AUTOSAR XML (schema 00046)
package /ComponentTypes
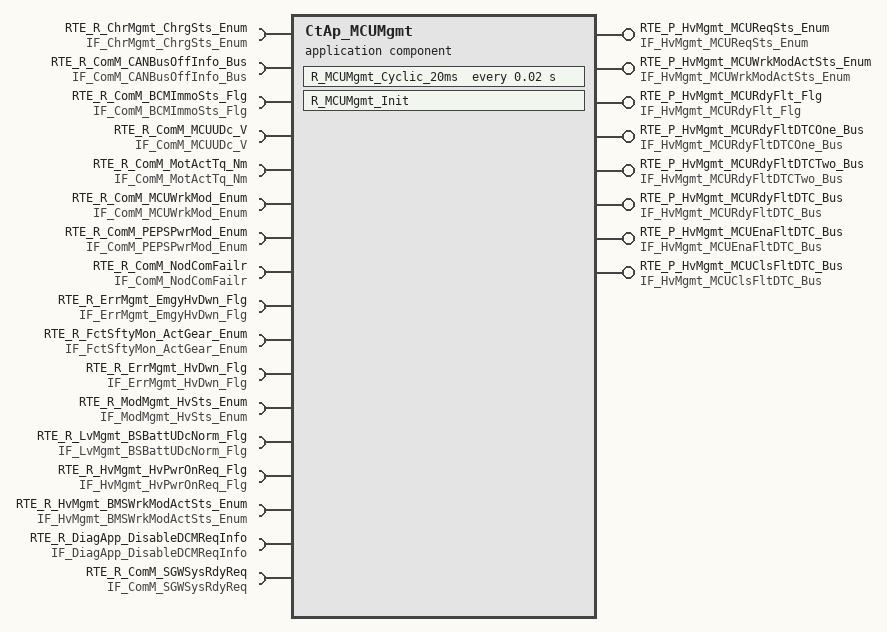
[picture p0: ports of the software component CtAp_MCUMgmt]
  application sw component type CtAp_MCUMgmt
    8 x provide port:
      RTE_P_HvMgmt_MCUReqSts_Enum: nonqueued-sender-com-spec{data-element=tec_HvMgmt_MCUReqSts_Enum, init-value=0}, provided-interface=IF_HvMgmt_MCUReqSts_Enum
      RTE_P_HvMgmt_MCUWrkModActSts_Enum: nonqueued-sender-com-spec{data-element=tec_HvMgmt_MCUWrkModActSts_Enum, init-value=0}, provided-interface=IF_HvMgmt_MCUWrkModActSts_Enum
      RTE_P_HvMgmt_MCURdyFlt_Flg: nonqueued-sender-com-spec{data-element=tec_HvMgmt_MCURdyFlt_Flg, init-value=0}, provided-interface=IF_HvMgmt_MCURdyFlt_Flg
      RTE_P_HvMgmt_MCURdyFltDTCOne_Bus: nonqueued-sender-com-spec{data-element=tec_HvMgmt_MCURdyFltDTCOne_Bus, init-value=fields=[HvMgmt_MonStatMCURdyFltDTCOne:0, HvMgmt_MonResMCURdyFltDTCOne:0, HvMgmt_ErrStatMCURdyFltDTCOne:0, HvMgmt_ErrResMCURdyFltDTCOne:0]}, provided-interface=IF_HvMgmt_MCURdyFltDTCOne_Bus
      RTE_P_HvMgmt_MCURdyFltDTCTwo_Bus: nonqueued-sender-com-spec{data-element=tec_HvMgmt_MCURdyFltDTCTwo_Bus, init-value=fields=[HvMgmt_MonStatMCURdyFltDTCTwo:0, HvMgmt_MonResMCURdyFltDTCTwo:0, HvMgmt_ErrStatMCURdyFltDTCTwo:0, HvMgmt_ErrResMCURdyFltDTCTwo:0]}, provided-interface=IF_HvMgmt_MCURdyFltDTCTwo_Bus
      RTE_P_HvMgmt_MCURdyFltDTC_Bus: nonqueued-sender-com-spec{data-element=tec_HvMgmt_MCURdyFltDTC_Bus, init-value=fields=[HvMgmt_MonStatMCURdyFltDTC:0, HvMgmt_MonResMCURdyFltDTC:0, HvMgmt_ErrStatMCURdyFltDTC:0, HvMgmt_ErrResMCURdyFltDTC:0]}, provided-interface=IF_HvMgmt_MCURdyFltDTC_Bus
      RTE_P_HvMgmt_MCUEnaFltDTC_Bus: nonqueued-sender-com-spec{data-element=tec_HvMgmt_MCUEnaFltDTC_Bus, init-value=fields=[HvMgmt_MonStatMCUEnaFltDTC:0, HvMgmt_MonResMCUEnaFltDTC:0, HvMgmt_ErrStatMCUEnaFltDTC:0, HvMgmt_ErrResMCUEnaFltDTC:0]}, provided-interface=IF_HvMgmt_MCUEnaFltDTC_Bus
      RTE_P_HvMgmt_MCUClsFltDTC_Bus: nonqueued-sender-com-spec{data-element=tec_HvMgmt_MCUClsFltDTC_Bus, init-value=fields=[HvMgmt_MonStatMCUClsFltDTC:0, HvMgmt_MonResMCUClsFltDTC:0, HvMgmt_ErrStatMCUClsFltDTC:0, HvMgmt_ErrResMCUClsFltDTC:0]}, provided-interface=IF_HvMgmt_MCUClsFltDTC_Bus
    17 x require port:
      RTE_R_ChrMgmt_ChrgSts_Enum: nonqueued-receiver-com-spec{data-element=tec_ChrMgmt_ChrgSts_Enum, filter=data-filter-type=ALWAYS, init-value=0}, required-interface=IF_ChrMgmt_ChrgSts_Enum
      RTE_R_ComM_CANBusOffInfo_Bus: required-interface=IF_ComM_CANBusOffInfo_Bus
        required-com-specs:
          data-element=tec_ComM_EPTCANBusOffInfo_Bus, filter=data-filter-type=ALWAYS, init-value=fields=[ComM_MonStatEPTCANBusOffInfo:0, ComM_MonResEPTCANBusOffInfo:0, ComM_ErrStatEPTCANBusOffInfo:0, ComM_ErrResEPTCANBusOffInfo:0]
          data-element=tec_ComM_CHCANBusOffInfo_Bus, filter=data-filter-type=ALWAYS, init-value=fields=[ComM_MonStatCHCANBusOffInfo:0, ComM_MonResCHCANBusOffInfo:0, ComM_ErrStatCHCANBusOffInfo:0, ComM_ErrResCHCANBusOffInfo:0]
          data-element=tec_ComM_EPTCANBusOffDTCInfo_Bus, filter=data-filter-type=ALWAYS, init-value=fields=[ComM_MonStatEPTCANBusOffDTCInfo:0, ComM_MonResEPTCANBusOffDTCInfo:0, ComM_ErrStatEPTCANBusOffDTCInfo:0, ComM_ErrResEPTCANBusOffDTCInfo:0]
          data-element=tec_ComM_CHCANBusOffDTCInfo_Bus, filter=data-filter-type=ALWAYS, init-value=fields=[ComM_MonStatCHCANBusOffDTCInfo:0, ComM_MonResCHCANBusOffDTCInfo:0, ComM_ErrStatCHCANBusOffDTCInfo:0, ComM_ErrResCHCANBusOffDTCInfo:0]
          data-element=tec_ComM_DCCANBusOffDTCInfo_Bus, init-value=fields=[ComM_MonStatDCCANDTCBusOffInfo:0, ComM_MonResDCCANDTCBusOffInfo:0, ComM_ErrStatDCCANDTCBusOffInfo:0, ComM_ErrResDCCANDTCBusOffInfo:0]
          data-element=tec_ComM_DCCANBusOffInfo_Bus, init-value=fields=[ComM_MonStatDCCANBusOffInfo:0, ComM_MonResDCCANBusOffInfo:0, ComM_ErrStatDCCANBusOffInfo:0, ComM_ErrResDCCANBusOffInfo:0]
      RTE_R_ComM_BCMImmoSts_Flg: nonqueued-receiver-com-spec{data-element=tec_ComM_BCMImmoSts_Flg, filter=data-filter-type=ALWAYS, init-value=0}, required-interface=IF_ComM_BCMImmoSts_Flg
      RTE_R_ComM_MCUUDc_V: nonqueued-receiver-com-spec{data-element=tec_ComM_MCUUDc_V, filter=data-filter-type=ALWAYS, init-value=0}, required-interface=IF_ComM_MCUUDc_V
      RTE_R_ComM_MotActTq_Nm: nonqueued-receiver-com-spec{data-element=tec_ComM_MotActTq_Nm, filter=data-filter-type=ALWAYS, init-value=0}, required-interface=IF_ComM_MotActTq_Nm
      RTE_R_ComM_MCUWrkMod_Enum: nonqueued-receiver-com-spec{data-element=tec_ComM_MCUWrkMod_Enum, filter=data-filter-type=ALWAYS, init-value=0}, required-interface=IF_ComM_MCUWrkMod_Enum
      RTE_R_ComM_PEPSPwrMod_Enum: nonqueued-receiver-com-spec{data-element=tec_ComM_PEPSPwrMod_Enum, filter=data-filter-type=ALWAYS, init-value=0}, required-interface=IF_ComM_PEPSPwrMod_Enum
      RTE_R_ComM_NodComFailr: required-interface=IF_ComM_NodComFailr
        required-com-specs:
          data-element=tec_ComM_SGWNodComFailr_Flg, filter=data-filter-type=ALWAYS, init-value=0
          data-element=tec_ComM_CGWNodComFailr_Flg, filter=data-filter-type=ALWAYS, init-value=0
          data-element=tec_ComM_TCUNodComFailr_Flg, filter=data-filter-type=ALWAYS, init-value=0
          data-element=tec_ComM_BCMNodComFailr_Flg, filter=data-filter-type=ALWAYS, init-value=0
          data-element=tec_ComM_PRNDNodComFailr_Flg, filter=data-filter-type=ALWAYS, init-value=0
          data-element=tec_ComM_IVINodComFailr_Flg, filter=data-filter-type=ALWAYS, init-value=0
          data-element=tec_ComM_DCDCNodComFailr_Flg, filter=data-filter-type=ALWAYS, init-value=0
          data-element=tec_ComM_OBCNodComFailr_Flg, filter=data-filter-type=ALWAYS, init-value=0
          data-element=tec_ComM_CHIBSNodComFailr_Flg, filter=data-filter-type=ALWAYS, init-value=0
          data-element=tec_ComM_MCUNodComFailr_Flg, filter=data-filter-type=ALWAYS, init-value=0
          data-element=tec_ComM_EVCOMNodComFailr_Flg, filter=data-filter-type=ALWAYS, init-value=0
          data-element=tec_ComM_EPTIBSNodComFailr_Flg, filter=data-filter-type=ALWAYS, init-value=0
          data-element=tec_ComM_DCMNodComFailr_Flg, filter=data-filter-type=ALWAYS, init-value=0
          data-element=tec_ComM_BMSNodComFailr_Flg, filter=data-filter-type=ALWAYS, init-value=0
          data-element=tec_ComM_ACUNodComFailr_Flg, filter=data-filter-type=ALWAYS, init-value=0
          data-element=tec_ComM_APTCNodComFailr_Flg, filter=data-filter-type=ALWAYS, init-value=0
          data-element=tec_ComM_ADCUNodComFailr_Flg, filter=data-filter-type=ALWAYS, init-value=0
          data-element=tec_ComM_DCMRRNodComFailr_Flg, filter=data-filter-type=ALWAYS, init-value=0
          data-element=tec_ComM_DCMRLNodComFailr_Flg, filter=data-filter-type=ALWAYS, init-value=0
          data-element=tec_ComM_DCMFRNodComFailr_Flg, filter=data-filter-type=ALWAYS, init-value=0
          data-element=tec_ComM_DCMFLNodComFailr_Flg, filter=data-filter-type=ALWAYS, init-value=0
          data-element=tec_ComM_SGWCHNodComFailr_Flg, init-value=0
      RTE_R_ErrMgmt_EmgyHvDwn_Flg: nonqueued-receiver-com-spec{data-element=tec_ErrMgmt_EmgyHvDwn_Flg, filter=data-filter-type=ALWAYS, init-value=0}, required-interface=IF_ErrMgmt_EmgyHvDwn_Flg
      RTE_R_FctSftyMon_ActGear_Enum: nonqueued-receiver-com-spec{data-element=tec_FctSftyMon_ActGear_Enum, filter=data-filter-type=ALWAYS, init-value=0}, required-interface=IF_FctSftyMon_ActGear_Enum
      RTE_R_ErrMgmt_HvDwn_Flg: nonqueued-receiver-com-spec{data-element=tec_ErrMgmt_HvDwn_Flg, filter=data-filter-type=ALWAYS, init-value=0}, required-interface=IF_ErrMgmt_HvDwn_Flg
      RTE_R_ModMgmt_HvSts_Enum: nonqueued-receiver-com-spec{data-element=tec_ModMgmt_HvSts_Enum, filter=data-filter-type=ALWAYS, init-value=0}, required-interface=IF_ModMgmt_HvSts_Enum
      RTE_R_LvMgmt_BSBattUDcNorm_Flg: nonqueued-receiver-com-spec{data-element=tec_LvMgmt_BSBattUDcNorm_Flg, filter=data-filter-type=ALWAYS, init-value=0}, required-interface=IF_LvMgmt_BSBattUDcNorm_Flg
      RTE_R_HvMgmt_HvPwrOnReq_Flg: nonqueued-receiver-com-spec{data-element=tec_HvMgmt_HvPwrOnReq_Flg, filter=data-filter-type=ALWAYS, init-value=0}, required-interface=IF_HvMgmt_HvPwrOnReq_Flg
      RTE_R_HvMgmt_BMSWrkModActSts_Enum: nonqueued-receiver-com-spec{data-element=tec_HvMgmt_BMSWrkModActSts_Enum, filter=data-filter-type=ALWAYS, init-value=0}, required-interface=IF_HvMgmt_BMSWrkModActSts_Enum
      RTE_R_DiagApp_DisableDCMReqInfo: nonqueued-receiver-com-spec{data-element=tec_DiagApp_DisableDCMReqInfo, filter=data-filter-type=ALWAYS, init-value=0}, required-interface=IF_DiagApp_DisableDCMReqInfo
      RTE_R_ComM_SGWSysRdyReq: nonqueued-receiver-com-spec{data-element=tec_ComM_SGWSysRdyReq, filter=data-filter-type=ALWAYS, init-value=0}, required-interface=IF_ComM_SGWSysRdyReq
    behavior CtAp_MCUMgmt_InternalBehavior
      timing event TMT_R_MCUMgmt_Cyclic_20ms: start-on-event=R_MCUMgmt_Cyclic_20ms, period=0.02
      init event CtAp_MCUMgmt_InitEvent: start-on-event=R_MCUMgmt_Init
      runnable R_MCUMgmt_Cyclic_20ms
        data-receive-point-by-arguments:
          18 x access:
            REC_RTE_R_ChrMgmt_ChrgSts_Enum_tec_ChrMgmt_ChrgSts_Enum: accessed-variable=RTE_R_ChrMgmt_ChrgSts_Enum.tec_ChrMgmt_ChrgSts_Enum
            REC_RTE_R_ComM_BCMImmoSts_Flg_tec_ComM_BCMImmoSts_Flg: accessed-variable=RTE_R_ComM_BCMImmoSts_Flg.tec_ComM_BCMImmoSts_Flg
            REC_RTE_R_ComM_CANBusOffInfo_Bus_tec_ComM_EPTCANBusOffInfo_Bus: accessed-variable=RTE_R_ComM_CANBusOffInfo_Bus.tec_ComM_EPTCANBusOffInfo_Bus
            REC_RTE_R_ComM_MCUUDc_V_tec_ComM_MCUUDc_V: accessed-variable=RTE_R_ComM_MCUUDc_V.tec_ComM_MCUUDc_V
            REC_RTE_R_ComM_MCUWrkMod_Enum_tec_ComM_MCUWrkMod_Enum: accessed-variable=RTE_R_ComM_MCUWrkMod_Enum.tec_ComM_MCUWrkMod_Enum
            REC_RTE_R_ComM_MotActTq_Nm_tec_ComM_MotActTq_Nm: accessed-variable=RTE_R_ComM_MotActTq_Nm.tec_ComM_MotActTq_Nm
            REC_RTE_R_ComM_NodComFailr_tec_ComM_BCMNodComFailr_Flg: accessed-variable=RTE_R_ComM_NodComFailr.tec_ComM_BCMNodComFailr_Flg
            REC_RTE_R_ErrMgmt_EmgyHvDwn_Flg_tec_ErrMgmt_EmgyHvDwn_Flg: accessed-variable=RTE_R_ErrMgmt_EmgyHvDwn_Flg.tec_ErrMgmt_EmgyHvDwn_Flg
            REC_RTE_R_ErrMgmt_HvDwn_Flg_tec_ErrMgmt_HvDwn_Flg: accessed-variable=RTE_R_ErrMgmt_HvDwn_Flg.tec_ErrMgmt_HvDwn_Flg
            REC_RTE_R_FctSftyMon_ActGear_Enum_tec_FctSftyMon_ActGear_Enum: accessed-variable=RTE_R_FctSftyMon_ActGear_Enum.tec_FctSftyMon_ActGear_Enum
            REC_RTE_R_HvMgmt_BMSWrkModActSts_Enum_tec_HvMgmt_BMSWrkModActSts_Enum: accessed-variable=RTE_R_HvMgmt_BMSWrkModActSts_Enum.tec_HvMgmt_BMSWrkModActSts_Enum
            REC_RTE_R_HvMgmt_HvPwrOnReq_Flg_tec_HvMgmt_HvPwrOnReq_Flg: accessed-variable=RTE_R_HvMgmt_HvPwrOnReq_Flg.tec_HvMgmt_HvPwrOnReq_Flg
            REC_RTE_R_LvMgmt_BSBattUDcNorm_Flg_tec_LvMgmt_BSBattUDcNorm_Flg: accessed-variable=RTE_R_LvMgmt_BSBattUDcNorm_Flg.tec_LvMgmt_BSBattUDcNorm_Flg
            REC_RTE_R_ModMgmt_HvSts_Enum_tec_ModMgmt_HvSts_Enum: accessed-variable=RTE_R_ModMgmt_HvSts_Enum.tec_ModMgmt_HvSts_Enum
            REC_RTE_R_ComM_PEPSPwrMod_Enum_tec_ComM_PEPSPwrMod_Enum: accessed-variable=RTE_R_ComM_PEPSPwrMod_Enum.tec_ComM_PEPSPwrMod_Enum
            REC_RTE_R_ComM_NodComFailr_tec_ComM_MCUNodComFailr_Flg: accessed-variable=RTE_R_ComM_NodComFailr.tec_ComM_MCUNodComFailr_Flg
            REC_RTE_R_DiagApp_DisableDCMReqInfo_tec_DiagApp_DisableDCMReqInfo: accessed-variable=RTE_R_DiagApp_DisableDCMReqInfo.tec_DiagApp_DisableDCMReqInfo
            REC_RTE_R_ComM_SGWSysRdyReq_tec_ComM_SGWSysRdyReq: accessed-variable=RTE_R_ComM_SGWSysRdyReq.tec_ComM_SGWSysRdyReq
        data-send-points:
          8 x access:
            SEND_RTE_P_HvMgmt_MCUClsFltDTC_Bus_tec_HvMgmt_MCUClsFltDTC_Bus: accessed-variable=RTE_P_HvMgmt_MCUClsFltDTC_Bus.tec_HvMgmt_MCUClsFltDTC_Bus
            SEND_RTE_P_HvMgmt_MCUEnaFltDTC_Bus_tec_HvMgmt_MCUEnaFltDTC_Bus: accessed-variable=RTE_P_HvMgmt_MCUEnaFltDTC_Bus.tec_HvMgmt_MCUEnaFltDTC_Bus
            SEND_RTE_P_HvMgmt_MCURdyFltDTCOne_Bus_tec_HvMgmt_MCURdyFltDTCOne_Bus: accessed-variable=RTE_P_HvMgmt_MCURdyFltDTCOne_Bus.tec_HvMgmt_MCURdyFltDTCOne_Bus
            SEND_RTE_P_HvMgmt_MCURdyFltDTCTwo_Bus_tec_HvMgmt_MCURdyFltDTCTwo_Bus: accessed-variable=RTE_P_HvMgmt_MCURdyFltDTCTwo_Bus.tec_HvMgmt_MCURdyFltDTCTwo_Bus
            SEND_RTE_P_HvMgmt_MCURdyFltDTC_Bus_tec_HvMgmt_MCURdyFltDTC_Bus: accessed-variable=RTE_P_HvMgmt_MCURdyFltDTC_Bus.tec_HvMgmt_MCURdyFltDTC_Bus
            SEND_RTE_P_HvMgmt_MCURdyFlt_Flg_tec_HvMgmt_MCURdyFlt_Flg: accessed-variable=RTE_P_HvMgmt_MCURdyFlt_Flg.tec_HvMgmt_MCURdyFlt_Flg
            SEND_RTE_P_HvMgmt_MCUReqSts_Enum_tec_HvMgmt_MCUReqSts_Enum: accessed-variable=RTE_P_HvMgmt_MCUReqSts_Enum.tec_HvMgmt_MCUReqSts_Enum
            SEND_RTE_P_HvMgmt_MCUWrkModActSts_Enum_tec_HvMgmt_MCUWrkModActSts_Enum: accessed-variable=RTE_P_HvMgmt_MCUWrkModActSts_Enum.tec_HvMgmt_MCUWrkModActSts_Enum
      runnable R_MCUMgmt_Init
  swc implementation CtAp_MCUMgmt_Implementation: behavior=CtAp_MCUMgmt_InternalBehavior
